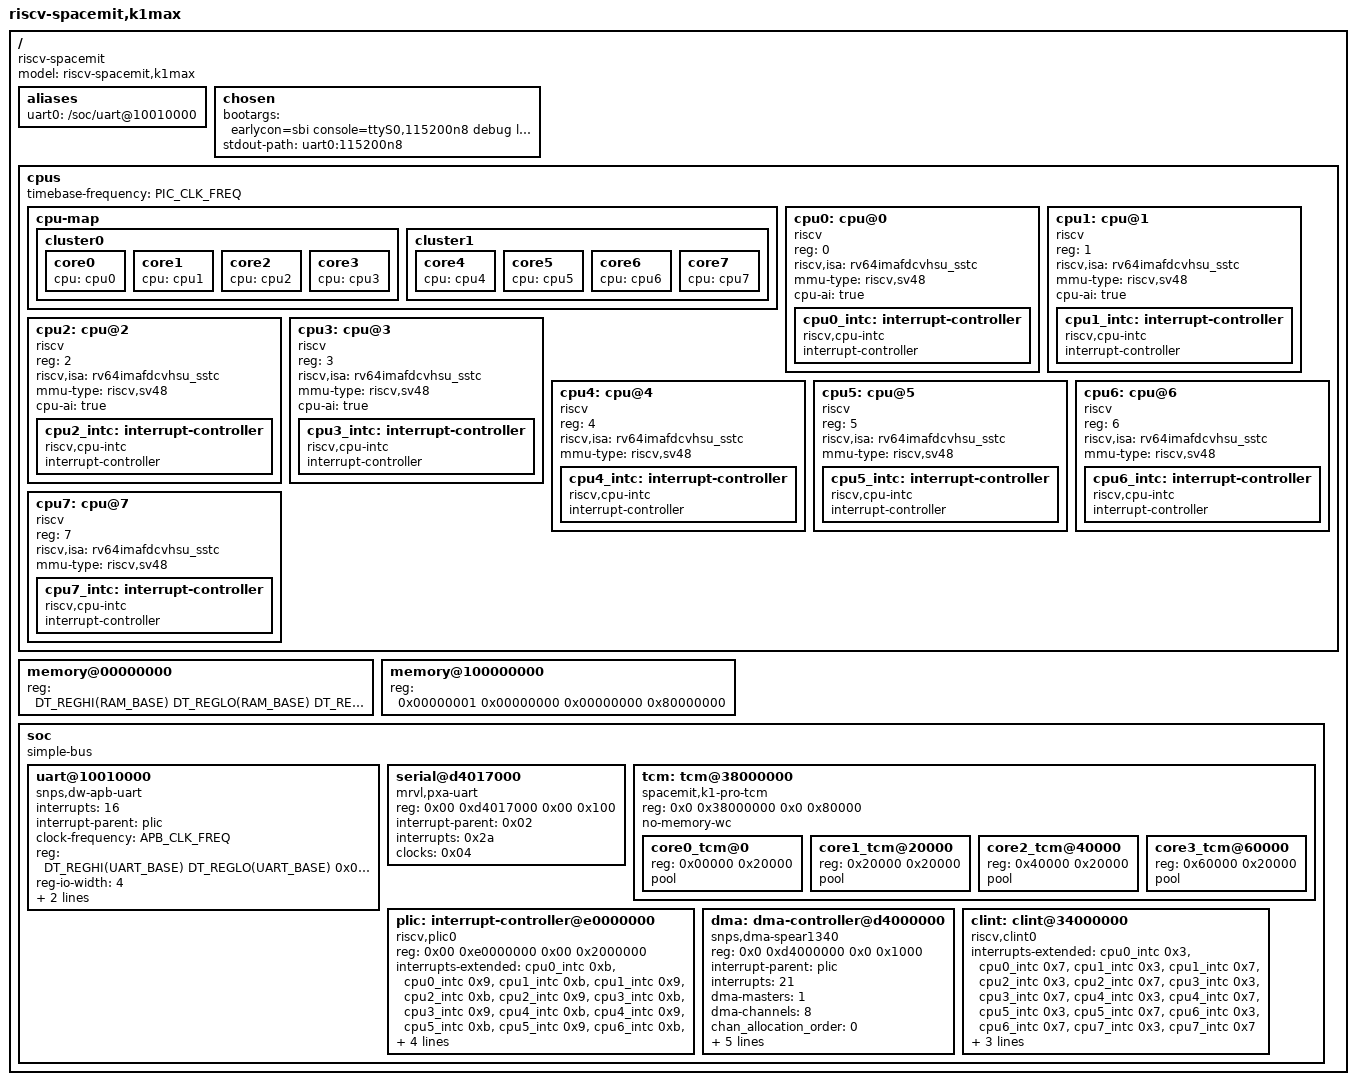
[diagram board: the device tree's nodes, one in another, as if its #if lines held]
#include <target/arch.h>
#include <dt-bindings/clock/sbi-clock-k1max.h>

/dts-v1/;

/ {
	#address-cells = <0x2>;
	#size-cells = <0x2>;
	compatible = "riscv-spacemit";
	model = "riscv-spacemit,k1max";

	aliases {
		uart0 = "/soc/uart@10010000";
	};

	chosen {
#ifdef CONFIG_K1X_UART_DTS_CON
		bootargs = "earlycon=sbi console=ttyS0,115200n8 debug loglevel=8,initcall_debug=1 rdinit=/sdfirm_init";
		stdout-path = "uart0:115200n8";
#else
		bootargs = "console=hvc0 earlycon=sbi rdinit=/sdfirm_init";
#endif
	};

	cpus {
		#address-cells = <0x1>;
		#size-cells = <0x0>;
		timebase-frequency = <PIC_CLK_FREQ>;

		cpu-map {
			cluster0 {
				core0 {
					cpu = <&cpu0>;
				};
#ifdef CONFIG_SMP
				core1 {
					cpu = <&cpu1>;
				};
#endif
#if CONFIG_K1X_SMP_CPUS >= 4
				core2 {
					cpu = <&cpu2>;
				};
				core3 {
					cpu = <&cpu3>;
				};
#endif
			};
#if CONFIG_K1X_SMP_CPUS >= 8
			cluster1 {
				core4 {
					cpu = <&cpu4>;
				};
				core5 {
					cpu = <&cpu5>;
				};
				core6 {
					cpu = <&cpu6>;
				};
				core7 {
					cpu = <&cpu7>;
				};
			};
#endif
		};

		cpu0: cpu@0 {
			device_type = "cpu";
			reg = <0>;
			status = "okay";
			compatible = "riscv";
			riscv,isa = "rv64imafdcvhsu_sstc";
			mmu-type = "riscv,sv48";
			cpu-ai = "true";

			cpu0_intc: interrupt-controller {
				#interrupt-cells = <0x1>;
				interrupt-controller;
				compatible = "riscv,cpu-intc";
			};
		};
#ifdef CONFIG_SMP
		cpu1: cpu@1 {
			device_type = "cpu";
			reg = <1>;
			status = "okay";
			compatible = "riscv";
			riscv,isa = "rv64imafdcvhsu_sstc";
			mmu-type = "riscv,sv48";
			cpu-ai = "true";

			cpu1_intc: interrupt-controller {
				#interrupt-cells = <0x1>;
				interrupt-controller;
				compatible = "riscv,cpu-intc";
			};
		};
#endif
#if CONFIG_K1X_SMP_CPUS >= 4
		cpu2: cpu@2 {
			device_type = "cpu";
			reg = <2>;
			status = "okay";
			compatible = "riscv";
			riscv,isa = "rv64imafdcvhsu_sstc";
			mmu-type = "riscv,sv48";
			cpu-ai = "true";

			cpu2_intc: interrupt-controller {
				#interrupt-cells = <0x1>;
				interrupt-controller;
				compatible = "riscv,cpu-intc";
			};
		};
		cpu3: cpu@3 {
			device_type = "cpu";
			reg = <3>;
			status = "okay";
			compatible = "riscv";
			riscv,isa = "rv64imafdcvhsu_sstc";
			mmu-type = "riscv,sv48";
			cpu-ai = "true";

			cpu3_intc: interrupt-controller {
				#interrupt-cells = <0x1>;
				interrupt-controller;
				compatible = "riscv,cpu-intc";
			};
		};
#endif
#if CONFIG_K1X_SMP_CPUS >= 8
		cpu4: cpu@4 {
			device_type = "cpu";
			reg = <4>;
			status = "okay";
			compatible = "riscv";
			riscv,isa = "rv64imafdcvhsu_sstc";
			mmu-type = "riscv,sv48";

			cpu4_intc: interrupt-controller {
				#interrupt-cells = <0x1>;
				interrupt-controller;
				compatible = "riscv,cpu-intc";
			};
		};
		cpu5: cpu@5 {
			device_type = "cpu";
			reg = <5>;
			status = "okay";
			compatible = "riscv";
			riscv,isa = "rv64imafdcvhsu_sstc";
			mmu-type = "riscv,sv48";

			cpu5_intc: interrupt-controller {
				#interrupt-cells = <0x1>;
				interrupt-controller;
				compatible = "riscv,cpu-intc";
			};
		};
		cpu6: cpu@6 {
			device_type = "cpu";
			reg = <6>;
			status = "okay";
			compatible = "riscv";
			riscv,isa = "rv64imafdcvhsu_sstc";
			mmu-type = "riscv,sv48";

			cpu6_intc: interrupt-controller {
				#interrupt-cells = <0x1>;
				interrupt-controller;
				compatible = "riscv,cpu-intc";
			};
		};
		cpu7: cpu@7 {
			device_type = "cpu";
			reg = <7>;
			status = "okay";
			compatible = "riscv";
			riscv,isa = "rv64imafdcvhsu_sstc";
			mmu-type = "riscv,sv48";

			cpu7_intc: interrupt-controller {
				#interrupt-cells = <0x1>;
				interrupt-controller;
				compatible = "riscv,cpu-intc";
			};
		};
#endif
	};

	memory@00000000 {
		device_type = "memory";
		reg = <DT_REGHI(RAM_BASE) DT_REGLO(RAM_BASE)
		       DT_REGHI(RAM_SIZE) DT_REGLO(RAM_SIZE)
		>;
	};

#ifdef CONFIG_K1X_DDR_HIGH
	memory@100000000 {
		device_type = "memory";
		reg = <0x00000001 0x00000000
                       0x00000000 0x80000000
                >;
	};
#endif

	soc {
		#address-cells = <0x2>;
		#size-cells = <0x2>;
		compatible = "simple-bus";
		ranges;

#ifdef CONFIG_DW_UART
		uart@10010000 {
			interrupts = <16>;
			interrupt-parent = <&plic>;
			clock-frequency = <APB_CLK_FREQ>;
			reg = <DT_REGHI(UART_BASE) DT_REGLO(UART_BASE)
			       0x0 0x1000
			>;
			reg-io-width = <4>;
			reg-shift = <2>;
			hw-flow-control = "unsupport";
			compatible = "snps,dw-apb-uart";
#ifdef CONFIG_K1X_UART_DTS_CON
			status = "okay";
#else
			status = "disabled";
#endif
		};
#endif

#ifdef CONFIG_NS16550
		serial@d4017000 {
			compatible = "mrvl,pxa-uart";
			reg = <0x00 0xd4017000 0x00 0x100>;
			interrupt-parent = <0x02>;
			interrupts = <0x2a>;
			clocks = <0x04>;
			status = "ok";
		};
#endif

		tcm: tcm@38000000 {
			compatible = "spacemit,k1-pro-tcm";
			reg = <0x0 0x38000000 0x0 0x80000>;
			#address-cells = <1>;
			#size-cells = <1>;
			ranges = <0x0 0x0 0x38000000 0x80000>;
			no-memory-wc;

			core0_tcm@0 {
				reg = <0x00000 0x20000>;
				pool;
			};
			core1_tcm@20000 {
				reg = <0x20000 0x20000>;
				pool;
			};
			core2_tcm@40000 {
				reg = <0x40000 0x20000>;
				pool;
			};
			core3_tcm@60000 {
				reg = <0x60000 0x20000>;
				pool;
			};
		};

		plic: interrupt-controller@e0000000 {
			reg = <0x00 0xe0000000 0x00 0x2000000>;
			//reg = <DT_REGHI(PLIC_REG_BASE) DT_REGLO(PLIC_REG_BASE)
			//        0x0 0x08000000
			// >;
			interrupts-extended = <
				&cpu0_intc 0xb &cpu0_intc 0x9
#ifdef CONFIG_SMP
				&cpu1_intc 0xb &cpu1_intc 0x9
#endif
#if CONFIG_K1X_SMP_CPUS >= 4
				&cpu2_intc 0xb &cpu2_intc 0x9
				&cpu3_intc 0xb &cpu3_intc 0x9
#endif
#if CONFIG_K1X_SMP_CPUS >= 8
				&cpu4_intc 0xb &cpu4_intc 0x9
				&cpu5_intc 0xb &cpu5_intc 0x9
				&cpu6_intc 0xb &cpu6_intc 0x9
				&cpu7_intc 0xb &cpu7_intc 0x9
#endif
			>;
			interrupt-controller;
			riscv,ndev = <160>;
			riscv,max-priority = <7>;
			compatible = "riscv,plic0";
			#interrupt-cells = <0x1>;
			#address-cells = <0x0>;
		};

		dma: dma-controller@d4000000{
			compatible = "snps,dma-spear1340";
			reg = <0x0 0xd4000000 0x0 0x1000>;
			interrupt-parent = <&plic>;
			interrupts = <21>;
			dma-masters = <1>;
			dma-channels = <8>;
			chan_allocation_order = <0>;
			chan_priority = <0>;
			block_size = <2047>;
			data-width = <4 4 4 4>;
			snps,dma-protection-control = <1>;
			snps,max-burst-len = <16 16 16 16 16 16 16 16>;
			status = "okay";
		};

		clint: clint@34000000 {
			interrupts-extended = <
				&cpu0_intc 0x3 &cpu0_intc 0x7
#ifdef CONFIG_SMP
				&cpu1_intc 0x3 &cpu1_intc 0x7
#endif
#if CONFIG_K1X_SMP_CPUS >= 4
				&cpu2_intc 0x3 &cpu2_intc 0x7
				&cpu3_intc 0x3 &cpu3_intc 0x7
#endif
#if CONFIG_K1X_SMP_CPUS >= 8
				&cpu4_intc 0x3 &cpu4_intc 0x7
				&cpu5_intc 0x3 &cpu5_intc 0x7
				&cpu6_intc 0x3 &cpu6_intc 0x7
				&cpu7_intc 0x3 &cpu7_intc 0x7
#endif
			>;
			reg = <DT_REGHI(CLINT_BASE) DT_REGLO(CLINT_BASE)
			       0x0 0x00010000
			>;
			compatible = "riscv,clint0";
#ifdef CONFIG_ARCH_IS_MMIO_32BIT
			clint,has-no-64bit-mmio;
#endif
		};
	};
};
